# f28004x_xint_regs register map
Vendor: Texas Instruments
Peripheral module from a debugger description file (folder C2000).
Address unit: 16 bits
Registers are 16-bit, read-write, no defined reset value unless marked. A register's access mark holds for its fields unless they carry their own. Offsets are as the file gives them; lines under a group give offsets from that group; [hi:lo] are bit positions; {n}, {i} and the like mark numbered series; 'fields as' and 'values as' point back to an identical list; <NAME> marks a mode.

## XINT_REGS — XINT Registers
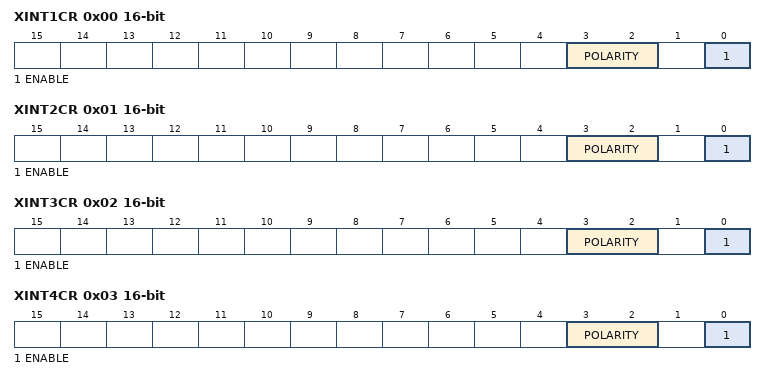
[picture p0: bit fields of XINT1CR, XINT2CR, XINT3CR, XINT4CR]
0x00 XINT1CR — XINT1 configuration register
  [3:2] POLARITY — XINT1 Polarity
  [0] ENABLE — XINT1 Enable
0x01 XINT2CR — XINT2 configuration register
  [3:2] POLARITY — XINT2 Polarity
  [0] ENABLE — XINT2 Enable
0x02 XINT3CR — XINT3 configuration register
  [3:2] POLARITY — XINT3 Polarity
  [0] ENABLE — XINT3 Enable
0x03 XINT4CR — XINT4 configuration register
  [3:2] POLARITY — XINT4 Polarity
  [0] ENABLE — XINT4 Enable
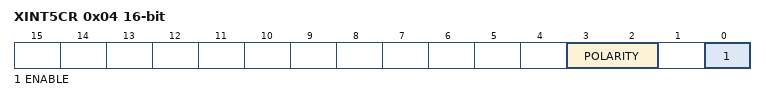
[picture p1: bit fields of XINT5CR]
0x04 XINT5CR — XINT5 configuration register
  [3:2] POLARITY — XINT5 Polarity
  [0] ENABLE — XINT5 Enable
{0x7+i} XINT{i}CTR ro (i=1..3) — XINT{i} counter register
  [15:0] INTCTR — XINT{i} Counter
